# S32K118_M0P register map
Vendor: NXP Semiconductors; File version: 1.1
CPU: CM0PLUS r0p0, little endian, MPU, FPU, VTOR, 4 interrupt priority bits
Registers are 32-bit, read-write, reset 0x0 unless marked. A register's access mark holds for its fields unless they carry their own. Offsets are from the block's base; [hi:lo] are bit positions; {n}, {i} and the like mark numbered series.

## SIM
Base 0x40048000
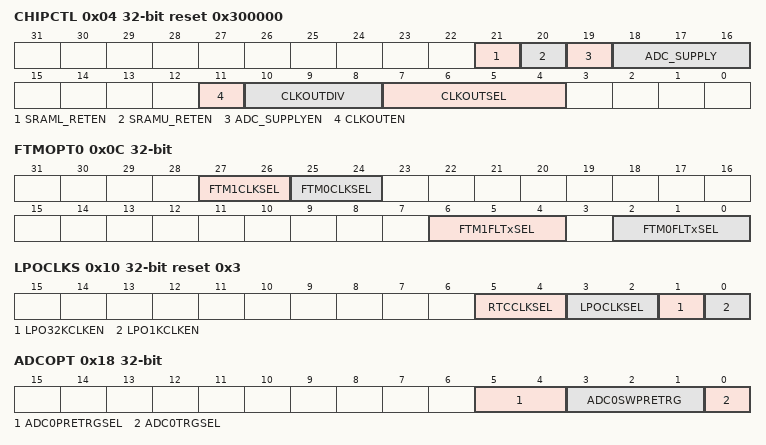
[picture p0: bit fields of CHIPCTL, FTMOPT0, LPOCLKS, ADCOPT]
0x04 CHIPCTL reset 0x300000 — Chip Control register
  [21] SRAML_RETEN
    0=SRAML contents are retained across resets; 1=No SRAML retention
  [20] SRAMU_RETEN
    0=SRAMU contents are retained across resets; 1=No SRAMU retention
  [19] ADC_SUPPLYEN
    0=Disable internal supply monitoring; 1=Enable internal supply monitoring
  [18:16] ADC_SUPPLY
    0=5 V input VDD supply (VDD); 1=5 V input analog supply (VDDA); 2=ADC Reference Supply (VREFH); 3=3.3 V Oscillator Regulator Output (VDD_3V); 4=3.3 V flash regulator output (VDD_flash_3V); 5=1.2 V core regulator output (VDD_LV)
  [11] CLKOUTEN — CLKOUT enable
    0=Clockout disable; 1=Clockout enable
  [10:8] CLKOUTDIV — CLKOUT Divide Ratio
    {v}=Divide by {v+1} (v=0..7)
  [7:4] CLKOUTSEL — CLKOUT Select
    0=SCG CLKOUT; 2=SOSC DIV2 CLK; 4=SIRC DIV2 CLK; 5=For S32K148: QSPI_SFIF_CLK_HYP_PREMUX: Divide by 2 clock (configured through SCLKCONFIG[5]) for HyperRAM going to sfif clock to QSPI; For others: Reserved; 6=FIRC DIV2 CLK; 7=HCLK; 8=For S32K14x: SPLL DIV2 CLK For S32K11x: Reserved; 9=BUS_CLK; 10=LPO128K_CLK; 11=For S32K148: QSPI_Module clock; For others: Reserved; 12=LPO_CLK as selected by SIM_LPOCLKS[LPOCLKSEL]; 13=For S32K148: QSPI_SFIF_CLK; For others: Reserved; 14=RTC_CLK as selected by SIM_LPOCLKS[RTCCLKSEL]; 15=For S32K148: QSPI_2xSFIF_CLK; For others: Reserved
0x0C FTMOPT0 — FTM Option Register 0
  [27:26] FTM1CLKSEL — FTM1 External Clock Pin Select
    0=FTM1 external clock driven by TCLK0 pin; 1=FTM1 external clock driven by TCLK1 pin; 2=FTM1 external clock driven by TCLK2 pin; 3=No clock input
  [25:24] FTM0CLKSEL — FTM0 External Clock Pin Select
    0=FTM0 external clock driven by TCLK0 pin; 1=FTM0 external clock driven by TCLK1 pin; 2=FTM0 external clock driven by TCLK2 pin; 3=No clock input
  [6:4] FTM1FLTxSEL — FTM1 Fault X Select
    0=FTM1_FLTx pin; 1=TRGMUX_FTM1 out
  [2:0] FTM0FLTxSEL — FTM0 Fault X Select
    0=FTM0_FLTx pin; 1=TRGMUX_FTM0 out
0x10 LPOCLKS reset 0x3 — LPO Clock Select Register
  [5:4] RTCCLKSEL — 32 kHz clock source select
    0=SOSCDIV1_CLK; 1=32 kHz LPO_CLK; 2=32 kHz RTC_CLKIN clock; 3=FIRCDIV1_CLK
  [3:2] LPOCLKSEL — LPO clock source select
    0=128 kHz LPO_CLK; 1=No clock; 2=32 kHz LPO_CLK which is derived from the 128 kHz LPO_CLK; 3=1 kHz LPO_CLK which is derived from the 128 kHz LPO_CLK
  [1] LPO32KCLKEN — 32 kHz LPO_CLK enable
    0=Disable 32 kHz LPO_CLK output; 1=Enable 32 kHz LPO_CLK output
  [0] LPO1KCLKEN — 1 kHz LPO_CLK enable
    0=Disable 1 kHz LPO_CLK output; 1=Enable 1 kHz LPO_CLK output
0x18 ADCOPT — ADC Options Register
  [5:4] ADC0PRETRGSEL — ADC0 pretrigger source select
    0=PDB pretrigger (default); 1=TRGMUX pretrigger; 2=Software pretrigger
  [3:1] ADC0SWPRETRG — ADC0 software pretrigger sources
    0=Software pretrigger disabled; {v}=Software pretrigger {v-4} (v=4..7)
  [0] ADC0TRGSEL — ADC0 trigger source select
    0=PDB output; 1=TRGMUX output
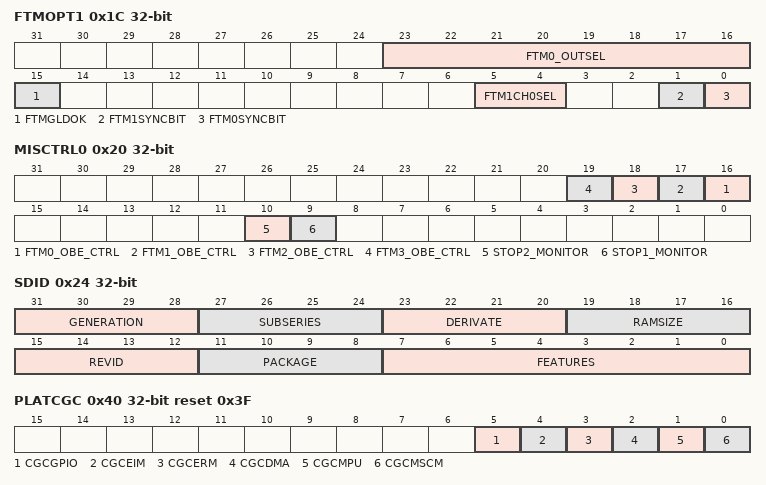
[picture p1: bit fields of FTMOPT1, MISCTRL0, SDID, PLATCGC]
0x1C FTMOPT1 — FTM Option Register 1
  [23:16] FTM0_OUTSEL — FTM0 channel modulation select with FTM1_CH1
    0=No modulation with FTM1_CH1; 1=Modulation with FTM1_CH1
  [15] FTMGLDOK — FTM global load enable
    0=FTM Global load mechanism disabled; 1=FTM Global load mechanism enabled
  [5:4] FTM1CH0SEL — FTM1 CH0 Select
    0=FTM1_CH0 input; 1=CMP0 output
  [1] FTM1SYNCBIT
  [0] FTM0SYNCBIT
0x20 MISCTRL0 — Miscellaneous control register 0
  [n+16] FTM{n}_OBE_CTRL (n=0..3) — FTM{n} OBE CTRL bit
    0=The FTM channel output is put to safe state when the FTM counter is enabled and the FTM channel output is enabled by Fault Control (FTM_MODE[FAULTM]!=2'b00 and FTM_FLTCTRL[FSTATE]=1'b0) and PWM is enabled (FTM_SC[PWMENn] = 1'b1). Otherwise the channel output is tristated.; 1=The FTM channel output state is retained when the channel is in output mode. The output channel is tristated when the channel is in input capture [DECAPEN=1'b0, COMBINE=1'b0, MSnB:MSnA=2'b00] or dual edge capture mode [DECAPEN=1'b1].
  [10] STOP2_MONITOR write-1-clears — STOP2 monitor bit
    0=System clock enabled or STOP2 entry aborted; 1=STOP2 entry successful
  [9] STOP1_MONITOR write-1-clears — STOP1 monitor bit
    0=Bus clock enabled or STOP1 entry aborted; 1=STOP1 entry successful
0x24 SDID ro reset not defined — System Device Identification Register
  [31:28] GENERATION — S32K product series generation
  [27:24] SUBSERIES
  [23:20] DERIVATE
  [19:16] RAMSIZE
  [15:12] REVID — Device revision number
  [11:8] PACKAGE
    2=48 LQFP; 3=64 LQFP; 4=100 LQFP; 6=144 LQFP; 7=176 LQFP; 8=100 MAP BGA
  [7:0] FEATURES
0x40 PLATCGC reset 0x3F — Platform Clock Gating Control Register
  [all] fields
    0=Clock disabled; 1=Clock enabled
  [5] CGCGPIO — GPIO Clock Gating Control
  [4] CGCEIM — EIM Clock Gating Control
  [3] CGCERM — ERM Clock Gating Control
  [2] CGCDMA — DMA Clock Gating Control
  [1] CGCMPU — MPU Clock Gating Control
  [0] CGCMSCM — MSCM Clock Gating Control
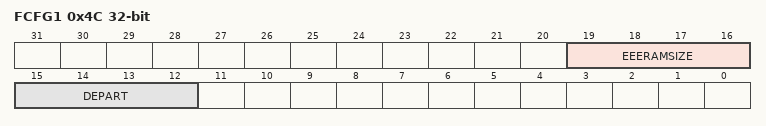
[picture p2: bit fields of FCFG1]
0x4C FCFG1 reset not defined — Flash Configuration Register 1
  [19:16] EEERAMSIZE ro — EEE SRAM SIZE
    2=4 KB; 3=2 KB; 4=1 KB; 5=512 Bytes; 6=256 Bytes; 7=128 Bytes; 8=64 Bytes; 9=32 Bytes; 15=0 Bytes
  [15:12] DEPART ro — FlexNVM partition
0x54 UIDH ro reset not defined — Unique Identification Register High
  [31:0] UID127_96 — Unique Identification
0x58 UIDMH ro reset not defined — Unique Identification Register Mid-High
  [31:0] UID95_64 — Unique Identification
0x5C UIDML ro reset not defined — Unique Identification Register Mid Low
  [31:0] UID63_32 — Unique Identification
0x60 UIDL ro reset not defined — Unique Identification Register Low
  [31:0] UID31_0 — Unique Identification
0x6C MISCTRL1 — Miscellaneous Control register 1
  [0] SW_TRG — Software trigger to TRGMUX. Writing to this bit generates software trigger to peripherals through TRGMUX (Refer to Figure: Trigger interconnectivity).

## Notices in the file
Copyright 2016-2022 NXP
NXP Confidential. This software is owned or controlled by NXP and may only be
used strictly in accordance with the applicable license terms. By expressly
accepting such terms or by downloading, installing, activating and/or otherwise
using the software, you are agreeing that you have read, and that you agree to
comply with and are bound by, such license terms. If you do not agree to be
bound by the applicable license terms, then you may not retain, install,
activate or otherwise use the software. The production use license in
Section 2.3 is expressly granted for this software.
